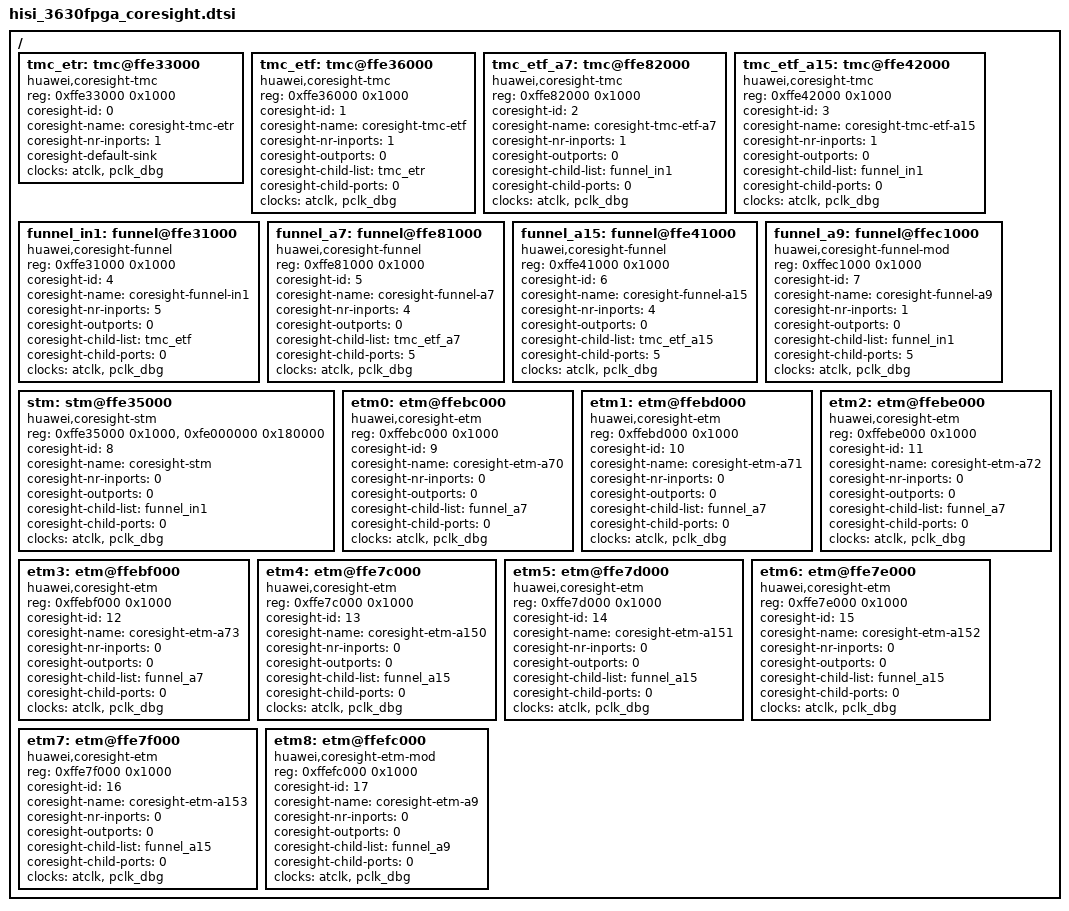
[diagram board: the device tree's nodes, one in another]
/* Copyright (c) 2013, hisi semiconductor co,ltd. All rights reserved.
 *
 * This program is free software; you can redistribute it and/or modify
 * it under the terms of the GNU General Public License version 2 and
 * only version 2 as published by the Free Software Foundation.
 *
 * This program is distributed in the hope that it will be useful,
 * but WITHOUT ANY WARRANTY; without even the implied warranty of
 * MERCHANTABILITY or FITNESS FOR A PARTICULAR PURPOSE.  See the
 * GNU General Public License for more details.
 */

/ {
	tmc_etr: tmc@ffe33000 {
		compatible = "huawei,coresight-tmc";
		reg = <0xffe33000 0x1000>;
		coresight-id = <0>;
		coresight-name = "coresight-tmc-etr";
		coresight-nr-inports = <1>;
		coresight-default-sink;
		clocks = <&atclk &pclk_dbg>;
		clock-names = "clk_at", "pclk_dbg";
	};

	tmc_etf: tmc@ffe36000 {
		compatible = "huawei,coresight-tmc";
		reg = <0xffe36000 0x1000>;
		coresight-id = <1>;
		coresight-name = "coresight-tmc-etf";
		coresight-nr-inports = <1>;
		coresight-outports = <0>;
		coresight-child-list = <&tmc_etr>;
		coresight-child-ports = <0>;
		clocks = <&atclk &pclk_dbg>;
		clock-names = "clk_at", "pclk_dbg";
	};

	tmc_etf_a7: tmc@ffe82000 {
		compatible = "huawei,coresight-tmc";
		reg = <0xffe82000 0x1000>;
		coresight-id = <2>;
		coresight-name = "coresight-tmc-etf-a7";
		coresight-nr-inports = <1>;
		coresight-outports = <0>;
		coresight-child-list = <&funnel_in1>;
		coresight-child-ports = <0>;
		clocks = <&atclk &pclk_dbg>;
		clock-names = "clk_at", "pclk_dbg";
	};

	tmc_etf_a15: tmc@ffe42000 {
		compatible = "huawei,coresight-tmc";
		reg = <0xffe42000 0x1000>;
		coresight-id = <3>;
		coresight-name = "coresight-tmc-etf-a15";
		coresight-nr-inports = <1>;
		coresight-outports = <0>;
		coresight-child-list = <&funnel_in1>;
		coresight-child-ports = <0>;
		clocks = <&atclk &pclk_dbg>;
		clock-names = "clk_at", "pclk_dbg";
	};

	funnel_in1: funnel@ffe31000 {
		compatible = "huawei,coresight-funnel";
		reg = <0xffe31000 0x1000>;
		coresight-id = <4>;
		coresight-name = "coresight-funnel-in1";
		coresight-nr-inports = <5>;
		coresight-outports = <0>;
		coresight-child-list = <&tmc_etf>;
		coresight-child-ports = <0>;
		clocks = <&atclk &pclk_dbg>;
		clock-names = "clk_at", "pclk_dbg";
	};

	funnel_a7: funnel@ffe81000 {
		compatible = "huawei,coresight-funnel";
		reg = <0xffe81000 0x1000>;
		coresight-id = <5>;
		coresight-name = "coresight-funnel-a7";
		coresight-nr-inports = <4>;
		coresight-outports = <0>;
		coresight-child-list = <&tmc_etf_a7>;
		coresight-child-ports = <5>;
		clocks = <&atclk &pclk_dbg>;
		clock-names = "clk_at", "pclk_dbg";
	};

	funnel_a15: funnel@ffe41000 {
		compatible = "huawei,coresight-funnel";
		reg = <0xffe41000 0x1000>;
		coresight-id = <6>;
		coresight-name = "coresight-funnel-a15";
		coresight-nr-inports = <4>;
		coresight-outports = <0>;
		coresight-child-list = <&tmc_etf_a15>;
		coresight-child-ports = <5>;
		clocks = <&atclk &pclk_dbg>;
		clock-names = "clk_at", "pclk_dbg";
	};

	funnel_a9: funnel@ffec1000 {
		compatible = "huawei,coresight-funnel-mod";
		reg = <0xffec1000 0x1000>;
		coresight-id = <7>;
		coresight-name = "coresight-funnel-a9";
		coresight-nr-inports = <1>;
		coresight-outports = <0>;
		coresight-child-list = <&funnel_in1>;
		coresight-child-ports = <5>;
		clocks = <&atclk &pclk_dbg>;
		clock-names = "clk_at", "pclk_dbg";
	};

	stm: stm@ffe35000 {
		compatible = "huawei,coresight-stm";
		reg = <0xffe35000 0x1000>,
		      <0xfe000000 0x180000>;
		coresight-id = <8>;
		coresight-name = "coresight-stm";
		coresight-nr-inports = <0>;
		coresight-outports = <0>;
		coresight-child-list = <&funnel_in1>;
		coresight-child-ports = <0>;
		clocks = <&atclk &pclk_dbg>;
		clock-names = "clk_at", "pclk_dbg";
	};

	etm0: etm@ffebc000 {
		compatible = "huawei,coresight-etm";
		reg = <0xffebc000 0x1000>;
		coresight-id = <9>;
		coresight-name = "coresight-etm-a70";
		coresight-nr-inports = <0>;
		coresight-outports = <0>;
		coresight-child-list = <&funnel_a7>;
		coresight-child-ports = <0>;
		clocks = <&atclk &pclk_dbg>;
		clock-names = "clk_at", "pclk_dbg";
	};

	etm1: etm@ffebd000 {
		compatible = "huawei,coresight-etm";
		reg = <0xffebd000 0x1000>;
		coresight-id = <10>;
		coresight-name = "coresight-etm-a71";
		coresight-nr-inports = <0>;
		coresight-outports = <0>;
		coresight-child-list = <&funnel_a7>;
		coresight-child-ports = <0>;
		clocks = <&atclk &pclk_dbg>;
		clock-names = "clk_at", "pclk_dbg";
	};

	etm2: etm@ffebe000 {
		compatible = "huawei,coresight-etm";
		reg = <0xffebe000 0x1000>;
		coresight-id = <11>;
		coresight-name = "coresight-etm-a72";
		coresight-nr-inports = <0>;
		coresight-outports = <0>;
		coresight-child-list = <&funnel_a7>;
		coresight-child-ports = <0>;
		clocks = <&atclk &pclk_dbg>;
		clock-names = "clk_at", "pclk_dbg";
	};

	etm3: etm@ffebf000 {
		compatible = "huawei,coresight-etm";
		reg = <0xffebf000 0x1000>;
		coresight-id = <12>;
		coresight-name = "coresight-etm-a73";
		coresight-nr-inports = <0>;
		coresight-outports = <0>;
		coresight-child-list = <&funnel_a7>;
		coresight-child-ports = <0>;
		clocks = <&atclk &pclk_dbg>;
		clock-names = "clk_at", "pclk_dbg";
	};

	etm4: etm@ffe7c000 {
		compatible = "huawei,coresight-etm";
		reg = <0xffe7c000 0x1000>;
		coresight-id = <13>;
		coresight-name = "coresight-etm-a150";
		coresight-nr-inports = <0>;
		coresight-outports = <0>;
		coresight-child-list = <&funnel_a15>;
		coresight-child-ports = <0>;
		clocks = <&atclk &pclk_dbg>;
		clock-names = "clk_at", "pclk_dbg";
	};

	etm5: etm@ffe7d000 {
		compatible = "huawei,coresight-etm";
		reg = <0xffe7d000 0x1000>;
		coresight-id = <14>;
		coresight-name = "coresight-etm-a151";
		coresight-nr-inports = <0>;
		coresight-outports = <0>;
		coresight-child-list = <&funnel_a15>;
		coresight-child-ports = <0>;
		clocks = <&atclk &pclk_dbg>;
		clock-names = "clk_at", "pclk_dbg";
	};

	etm6: etm@ffe7e000 {
		compatible = "huawei,coresight-etm";
		reg = <0xffe7e000 0x1000>;
		coresight-id = <15>;
		coresight-name = "coresight-etm-a152";
		coresight-nr-inports = <0>;
		coresight-outports = <0>;
		coresight-child-list = <&funnel_a15>;
		coresight-child-ports = <0>;
		clocks = <&atclk &pclk_dbg>;
		clock-names = "clk_at", "pclk_dbg";
	};

	etm7: etm@ffe7f000 {
		compatible = "huawei,coresight-etm";
		reg = <0xffe7f000 0x1000>;
		coresight-id = <16>;
		coresight-name = "coresight-etm-a153";
		coresight-nr-inports = <0>;
		coresight-outports = <0>;
		coresight-child-list = <&funnel_a15>;
		coresight-child-ports = <0>;
		clocks = <&atclk &pclk_dbg>;
		clock-names = "clk_at", "pclk_dbg";
	};

	etm8: etm@ffefc000 {
		compatible = "huawei,coresight-etm-mod";
		reg = <0xffefc000 0x1000>;
		coresight-id = <17>;
		coresight-name = "coresight-etm-a9";
		coresight-nr-inports = <0>;
		coresight-outports = <0>;
		coresight-child-list = <&funnel_a9>;
		coresight-child-ports = <0>;
		clocks = <&atclk &pclk_dbg>;
		clock-names = "clk_at", "pclk_dbg";
	};
};
